# SN32F400 register map
Vendor: SONiX Technology Co., Ltd.; Series: SN32F400; File version: 1.1
ARM 32-bit Cortex-M0 Microcontroller based device, CPU clock up to 60MHz, etc.
CPU: CM0 r0p0, little endian, no MPU, no FPU, 2 interrupt priority bits
Registers are 32-bit, read-write, reset 0x0 unless marked. A register's access mark holds for its fields unless they carry their own. Offsets are from the block's base; lines under a group give offsets from that group; [hi:lo] are bit positions; {n}, {i} and the like mark numbered series; 'fields as' and 'values as' point back to an identical list; <NAME> marks a mode.

## Memory map
0x1FFF2DF0 SN_UC size 0x2000 — UC Registers
0x40000000 SN_CT16B0 size 0x2000 — 16-bit Timer 0 with Capture function
0x40002000 SN_CT16B1 size 0x2000 — 16-bit Timer 1 with Capture function
0x4000A000 SN_CT16B5 size 0x2000 — 16-bit Timer 5 with Capture function
0x40010000 SN_WDT size 0x2000 — Watchdog Timer
0x40012000 SN_RTC size 0x2000 — Real-time Clock
0x40016000 SN_UART0 size 0x2000 — UART0
0x40018000 SN_I2C0 size 0x2000 — I2C0
0x4001C000 SN_SPI0 size 0x2000 — SPI0
0x40026000 SN_ADC size 0x2000 — ADC
0x40028000 SN_CMP size 0x2000 — Comparator
0x4002A000 SN_OPA size 0x2000 — OP Amplifier
0x40032000 SN_PMU size 0x2000 — Power Management Unit
0x40038000 SN_CRC size 0x2000 — Cyclic Redundancy Check
0x40042000 SN_PFPA size 0x2000 — Peripheral Function Pin Assignment
0x40044000 SN_GPIO0 size 0x2000 — General Purpose I/O
0x40046000 SN_GPIO1 size 0x2000 — General Purpose I/O
0x40048000 SN_GPIO2 size 0x2000 — General Purpose I/O
0x4004A000 SN_GPIO3 size 0x2000 — General Purpose I/O
0x40056000 SN_UART1 size 0x2000
0x4005E000 SN_SYS1 size 0x2000 — System Control Registers 1
0x40060000 SN_SYS0 size 0x2000 — System Control Registers 0
0x40062000 SN_FLASH size 0x2000 — FLASH Memory Control Registers
0x40072000 SN_DMA0 size 0x2000 — Direct Memory Access
0x40074000 SN_FOC size 0x2000 — BLDC FOC Function
0x40076000 SN_ACC size 0x2000 — Atan, Div and Sqrt Function

## Interrupts
0 NDT (SN_SYS0) — Noise Detection
1 DMA0 (SN_DMA0) — Direct Memory Access
2 CMP3 (SN_CMP) — CMP3 interrupt
6 SPI0 (SN_SPI0) — SPI0 interrupt
10 I2C0 (SN_I2C0) — I2C0 interrupt
12 CMP2 (SN_CMP) — CMP2 interrupt
13 UART0 (SN_UART0) — UART0 interrupt
14 UART1 (SN_UART1) — UART1 interrupt
15 CT16B0 (SN_CT16B0) — 16-bit Timer 0
16 CT16B1 (SN_CT16B1) — 16-bit Timer 1
17 SQRT (SN_ACC) — SQRT interrupt
18 CMP1 (SN_CMP) — CMP1 interrupt
19 ATAN (SN_ACC) — ATAN interrupt
20 DIV (SN_ACC) — DIV interrupt
21 CT16B5 (SN_CT16B5) — 16-bit Timer 5
22 FOC (SN_FOC) — FOC interrupt
23 RTC (SN_RTC) — Real-time Clock
24 ADC (SN_ADC) — ADC interrupt
25 WDT (SN_WDT) — Watchdog Timer
26 LVD (SN_SYS0) — Low Voltage Detection
27 CMP0 (SN_CMP) — CMP0 interrupt
28 P3 (SN_GPIO3) — GPIO3
29 P2 (SN_GPIO2) — GPIO2
30 P1 (SN_GPIO1) — GPIO1
31 P0 (SN_GPIO0) — GPIO0

## SN_UC — UC Registers
Base 0x1FFF2DF0
0x00 L4BYTE ro — Offset:0x00 UC Low 4 Byte register
  [31:0] L4BYTE — Offset:0x00 UC Low 4 Byte Register
0x08 H4BYTE ro — Offset:0x08 UC High 4 Byte register
  [31:0] H4BYTE — Offset:0x08 UC High 4 Byte Register

## SN_WDT — Watchdog Timer
Base 0x40010000
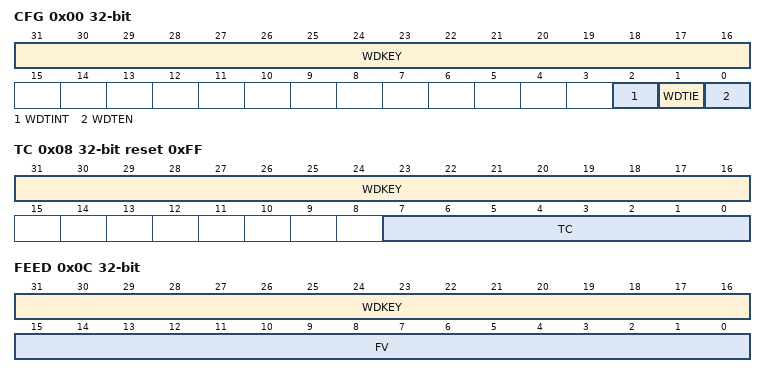
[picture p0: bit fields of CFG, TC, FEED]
0x00 CFG — Offset:0x00 WDT Configuration register
  [31:16] WDKEY wo — WDT register key
  [2] WDTINT — WDT interrupt flag
    0=No (No WDT time-out); 1=WDT time-out (WDT interrupt is triggered if WDTIE=1)
  [1] WDTIE — WDT interrupt enable
    0=Disable (WDT reset when WDT time-out); 1=Enable WDT interrupt
  [0] WDTEN — WDT enable
    0=Disable WDT; 1=Enable WDT
0x08 TC reset 0xFF — Offset:0x08 WDT Timer Constant register
  [31:16] WDKEY wo — WDT register key
  [7:0] TC — Watchdog timer constant reload value
0x0C FEED wo — Offset:0x0C WDT Feed register
  [31:16] WDKEY — WDT register key
  [15:0] FV — Watchdog feed value

## Licence text in the file
ARM Limited (ARM) is supplying this software for use with Cortex-M processor based microcontroller, but can be equally used for other suitable processor architectures. This file can be freely distributed. Modifications to this file shall be clearly marked. . THIS SOFTWARE IS PROVIDED "AS IS". NO WARRANTIES, WHETHER EXPRESS, IMPLIED. OR STATUTORY, INCLUDING, BUT NOT LIMITED TO, IMPLIED WARRANTIES OF. MERCHANTABILITY AND FITNESS FOR A PARTICULAR PURPOSE APPLY TO THIS SOFTWARE. ARM SHALL NOT, IN ANY CIRCUMSTANCES, BE LIABLE FOR SPECIAL, INCIDENTAL, OR. CONSEQUENTIAL DAMAGES, FOR ANY REASON WHATSOEVER.

## Notices in the file
Copyright (C) 2024 ARM Limited. All rights reserved.
